VERSION ""

NS_ :

BS_:

BU_: Gateway ECU Engine Transmission

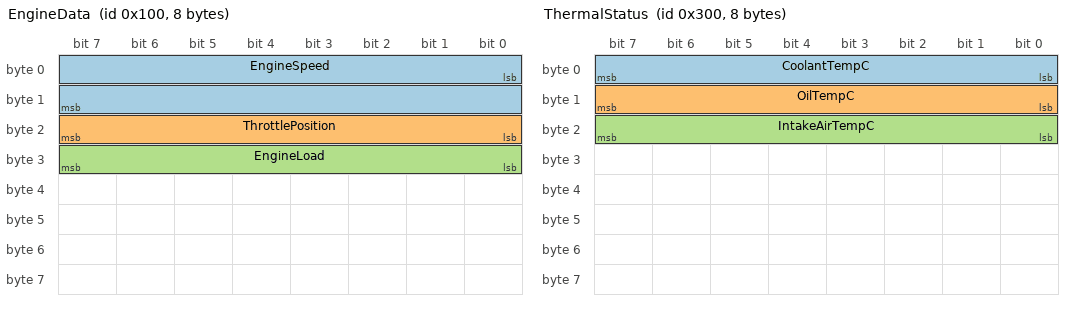
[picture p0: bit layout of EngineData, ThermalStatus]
BO_ 256 EngineData: 8 Engine
 SG_ EngineSpeed : 0|16@1+ (0.25,0) [0|8000] "rpm" Gateway
 SG_ ThrottlePosition : 16|8@1+ (0.392,0) [0|100] "%" Gateway
 SG_ EngineLoad : 24|8@1+ (0.392,0) [0|100] "%" Gateway

BO_ 512 VehicleSpeed: 8 Transmission
 SG_ VehicleSpeedKmh : 0|16@1+ (0.01,0) [0|300] "km/h" Gateway
 SG_ OdometerKm : 16|32@1+ (0.1,0) [0|1000000] "km" Gateway

BO_ 768 ThermalStatus: 8 Engine
 SG_ CoolantTempC : 0|8@1+ (1,-40) [-40|215] "degC" Gateway
 SG_ OilTempC : 8|8@1+ (1,-40) [-40|215] "degC" Gateway
 SG_ IntakeAirTempC : 16|8@1+ (1,-40) [-40|215] "degC" Gateway

BO_ 1024 BrakeStatus: 4 Gateway
 SG_ BrakePedalApplied : 0|1@1+ (1,0) [0|1] "" ECU
 SG_ BrakePressureBar : 1|15@1+ (0.1,0) [0|250] "bar" ECU
